# STM32MP157 register map
File version: 1.7
CPU: CM4 r0p1, little endian, no MPU, FPU, 4 interrupt priority bits
Registers are 32-bit, read-write, reset 0x0 unless marked. A register's access mark holds for its fields unless they carry their own. Offsets are from the block's base; [hi:lo] are bit positions.

## SPDIFRX
Base 0x4000D000
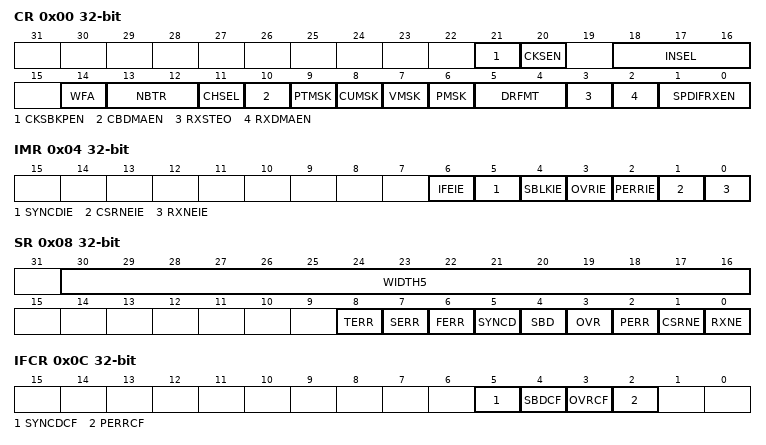
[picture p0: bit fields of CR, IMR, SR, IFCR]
0x00 CR — Control register
  [21] CKSBKPEN, [20] CKSEN, [18:16] INSEL, [14] WFA, [13:12] NBTR, [11] CHSEL, [10] CBDMAEN, [9] PTMSK, [8] CUMSK, [7] VMSK, [6] PMSK, [5:4] DRFMT, [3] RXSTEO, [2] RXDMAEN, [1:0] SPDIFRXEN
0x04 IMR — Interrupt mask register
  [6] IFEIE, [5] SYNCDIE, [4] SBLKIE, [3] OVRIE, [2] PERRIE, [1] CSRNEIE, [0] RXNEIE
0x08 SR ro — Status register
  [30:16] WIDTH5, [8] TERR, [7] SERR, [6] FERR, [5] SYNCD, [4] SBD, [3] OVR, [2] PERR, [1] CSRNE, [0] RXNE
0x0C IFCR — Interrupt flag clear register
  [5] SYNCDCF wo, [4] SBDCF wo, [3] OVRCF wo, [2] PERRCF wo
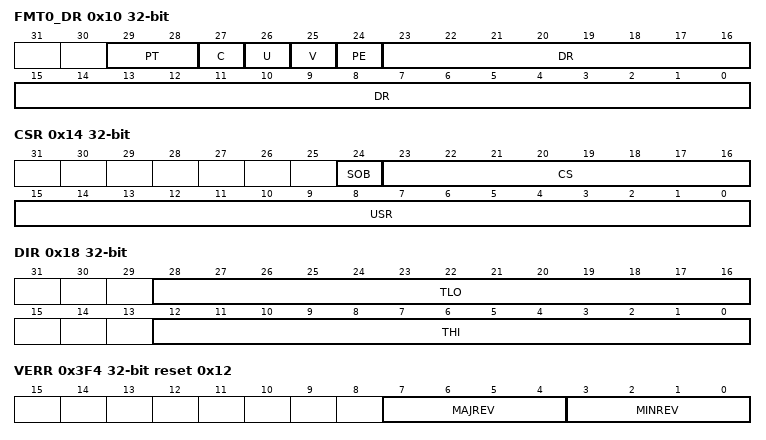
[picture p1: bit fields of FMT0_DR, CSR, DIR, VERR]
0x10 FMT0_DR ro — This register can take 3 different formats according to DRFMT. Here is the format when DRFMT = 00:
  [29:28] PT, [27] C, [26] U, [25] V, [24] PE, [23:0] DR
0x14 CSR ro — Channel status register
  [24] SOB, [23:16] CS, [15:0] USR
0x18 DIR ro — Debug information register
  [28:16] TLO, [12:0] THI
0x3F4 VERR ro reset 0x12 — SPDIFRX version register
  [7:4] MAJREV, [3:0] MINREV
0x3F8 IPIDR ro reset 0x130041 — SPDIFRX identification register
  [31:0] ID
0x3FC SIDR ro reset 0xA3C5DD01 — SPDIFRX size identification register
  [31:0] SID

## SPI1
Base 0x44004000
Same registers: SPI2 0x4000B000, SPI3 0x4000C000, SPI4 0x44005000, SPI5 0x44009000, SPI6 0x5C001000
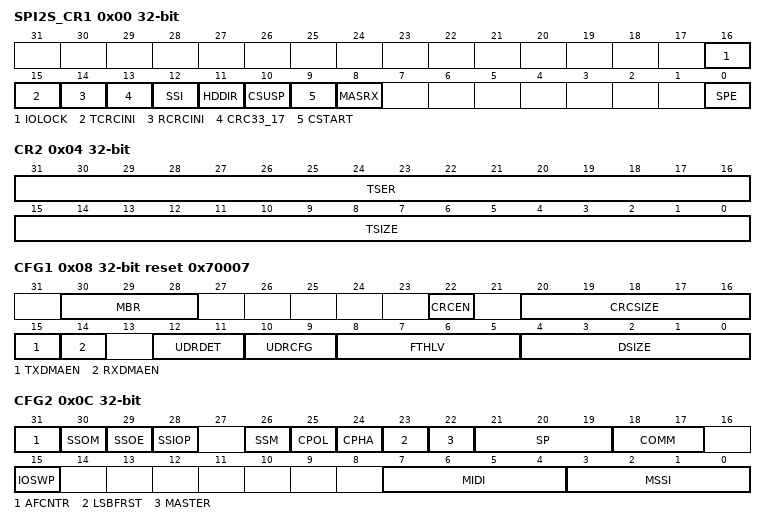
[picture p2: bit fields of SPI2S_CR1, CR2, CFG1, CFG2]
0x00 SPI2S_CR1 access per field — SPI/I2S control register 1
  [16] IOLOCK rw, [15] TCRCINI rw, [14] RCRCINI rw, [13] CRC33_17 rw, [12] SSI rw, [11] HDDIR rw, [10] CSUSP wo, [9] CSTART rw, [8] MASRX rw, [0] SPE rw
0x04 CR2 — SPI control register 2
  [31:16] TSER, [15:0] TSIZE
0x08 CFG1 reset 0x70007 — Content of this register is write protected when SPI is enabled
  [30:28] MBR, [22] CRCEN, [20:16] CRCSIZE, [15] TXDMAEN, [14] RXDMAEN, [12:11] UDRDET, [10:9] UDRCFG, [8:5] FTHLV, [4:0] DSIZE
0x0C CFG2 — The content of this register is write protected when SPI is enabled or IOLOCK bit is set at SPI2S_CR1 register.
  [31] AFCNTR, [30] SSOM, [29] SSOE, [28] SSIOP, [26] SSM, [25] CPOL, [24] CPHA, [23] LSBFRST, [22] MASTER, [21:19] SP, [18:17] COMM, [15] IOSWP, [7:4] MIDI, [3:0] MSSI
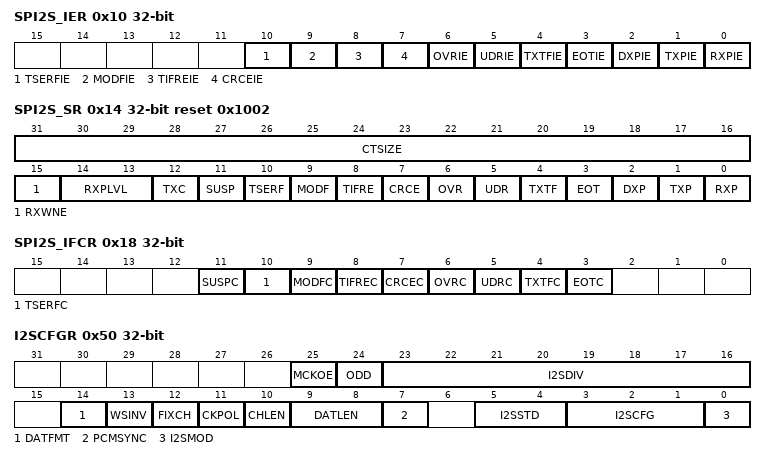
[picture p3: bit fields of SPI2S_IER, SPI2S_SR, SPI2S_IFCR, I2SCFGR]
0x10 SPI2S_IER — SPI/I2S interrupt enable register
  [10] TSERFIE, [9] MODFIE, [8] TIFREIE, [7] CRCEIE, [6] OVRIE, [5] UDRIE, [4] TXTFIE, [3] EOTIE, [2] DXPIE, [1] TXPIE, [0] RXPIE
0x14 SPI2S_SR ro reset 0x1002 — SPI/I2S status register
  [31:16] CTSIZE, [15] RXWNE, [14:13] RXPLVL, [12] TXC, [11] SUSP, [10] TSERF, [9] MODF, [8] TIFRE, [7] CRCE, [6] OVR, [5] UDR, [4] TXTF, [3] EOT, [2] DXP, [1] TXP, [0] RXP
0x18 SPI2S_IFCR wo — SPI/I2S interrupt/status flags clear register
  [11] SUSPC, [10] TSERFC, [9] MODFC, [8] TIFREC, [7] CRCEC, [6] OVRC, [5] UDRC, [4] TXTFC, [3] EOTC
0x20 SPI2S_TXDR wo — SPI/I2S transmit data register
0x20 TXDR16 16-bit wo (alternate view of TXDR) — Direct 16-bit access to transmit data register
  [15:0] TXDR — Transmit data register
0x20 TXDR8 8-bit wo (alternate view of TXDR) — Direct 8-bit access to transmit data register
  [7:0] TXDR — Transmit data register
0x30 SPI2S_RXDR ro — SPI/I2S receive data register
0x30 RXDR16 16-bit ro (alternate view of RXDR) — Direct 16-bit access to receive data register
  [15:0] RXDR — Receive data register
0x30 RXDR8 8-bit ro (alternate view of RXDR) — Direct 8-bit access to receive data register
  [7:0] RXDR — Receive data register
0x40 CRCPOLY reset 0x107 — SPI polynomial register
0x44 TXCRC ro — SPI transmitter CRC register
0x48 RXCRC ro — SPI receiver CRC register
0x4C UDRDR — SPI underrun data register
0x50 I2SCFGR — All documented bits in this register must be configured when the I2S is disabled (SPE = 0).These bits are not used in SPI mode except for I2SMOD which needs to be set to 0 in SPI mode.
  [25] MCKOE, [24] ODD, [23:16] I2SDIV, [14] DATFMT, [13] WSINV, [12] FIXCH, [11] CKPOL, [10] CHLEN, [9:8] DATLEN, [7] PCMSYNC, [5:4] I2SSTD, [3:1] I2SCFG, [0] I2SMOD
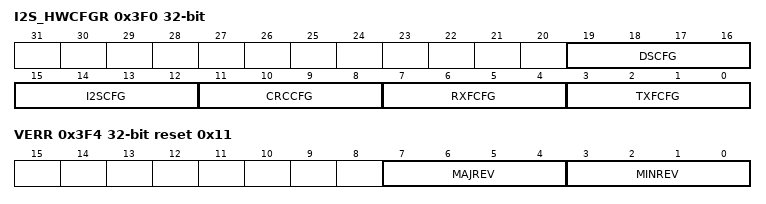
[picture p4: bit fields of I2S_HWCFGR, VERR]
0x3F0 I2S_HWCFGR ro — SPI/I2S hardware configuration register
  [19:16] DSCFG, [15:12] I2SCFG, [11:8] CRCCFG, [7:4] RXFCFG, [3:0] TXFCFG
0x3F4 VERR ro reset 0x11 — SPI/I2S version register
  [7:4] MAJREV, [3:0] MINREV
0x3F8 IPIDR ro reset 0x130022 — SPI/I2S identification register
  [31:0] ID
0x3FC SIDR ro reset 0xA3C5DD01 — SPI/I2S size identification register
  [31:0] SID
